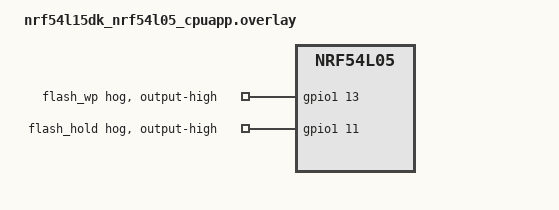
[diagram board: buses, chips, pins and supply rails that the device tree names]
/*
 * MCUboot overlay - Minimal configuration
 * 
 * MCUboot does not need external SPI flash for this project (secondary slot is
 * internal). Disable SPI00 here so MCUboot doesn't touch the SPIM hardware
 * instance before the application boots (peripheral state persists across the
 * chainload).
 */
&spi00 {
	status = "disabled";
};

/* CRITICAL: Prevent UICR from configuring pins as reset (nRESET/PSELRESET)
 * This ensures SPI CS pin (P2.05) and other SPI pins are available as GPIO
 * and not hijacked by reset functionality
 */
&uicr {
	/delete-property/ gpio-as-nreset;
};

&gpio1 {
	flash_wp: flash_wp {
		gpio-hog;
		gpios = <13 GPIO_ACTIVE_HIGH>;
		output-high;
	};
	flash_hold: flash_hold {
		gpio-hog;
		gpios = <11 GPIO_ACTIVE_HIGH>;
		output-high;
	};
};
